# STM32MP157 register map
File version: 1.6
CPU: CM4 r0p1, little endian, no MPU, FPU, 4 interrupt priority bits
Registers are 32-bit, read-write, reset 0x0 unless marked. A register's access mark holds for its fields unless they carry their own. Offsets are from the block's base; [hi:lo] are bit positions; {n}, {i} and the like mark numbered series; 'fields as' and 'values as' point back to an identical list.

## OTG
Base 0x49000000
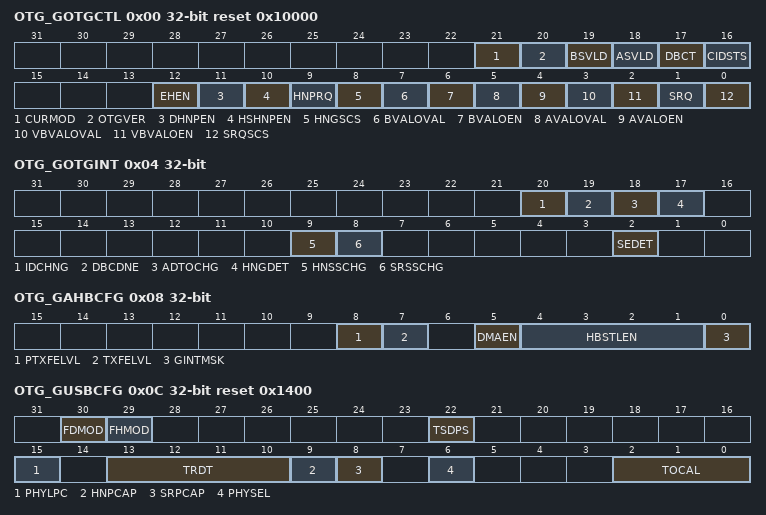
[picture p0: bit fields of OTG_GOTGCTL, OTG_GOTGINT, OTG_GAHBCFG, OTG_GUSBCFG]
0x00 OTG_GOTGCTL access per field reset 0x10000 — The OTG_GOTGCTL register controls the behavior and reflects the status of the OTG function of the core.
  [21] CURMOD ro, [20] OTGVER rw, [19] BSVLD ro, [18] ASVLD ro, [17] DBCT ro, [16] CIDSTS ro, [12] EHEN rw, [11] DHNPEN rw, [10] HSHNPEN rw, [9] HNPRQ rw, [8] HNGSCS ro, [7] BVALOVAL rw, [6] BVALOEN rw, [5] AVALOVAL rw, [4] AVALOEN rw, [3] VBVALOVAL rw, [2] VBVALOEN rw, [1] SRQ rw, [0] SRQSCS ro
0x04 OTG_GOTGINT — The application reads this register whenever there is an OTG interrupt and clears the bits in this register to clear the OTG interrupt.
  [20] IDCHNG, [19] DBCDNE, [18] ADTOCHG, [17] HNGDET, [9] HNSSCHG, [8] SRSSCHG, [2] SEDET
0x08 OTG_GAHBCFG — This register can be used to configure the core after power-on or a change in mode. This register mainly contains AHB system-related configuration parameters. Do not change this register after the initial programming. The application must program this register before starting any transactions on either the AHB or the USB.
  [8] PTXFELVL, [7] TXFELVL, [5] DMAEN, [4:1] HBSTLEN, [0] GINTMSK
0x0C OTG_GUSBCFG reset 0x1400 — This register can be used to configure the core after power-on or a changing to host mode or device mode. It contains USB and USB-PHY related configuration parameters. The application must program this register before starting any transactions on either the AHB or the USB. Do not make changes to this register after the initial programming.
  [30] FDMOD, [29] FHMOD, [22] TSDPS, [15] PHYLPC, [13:10] TRDT, [9] HNPCAP, [8] SRPCAP, [6] PHYSEL, [2:0] TOCAL
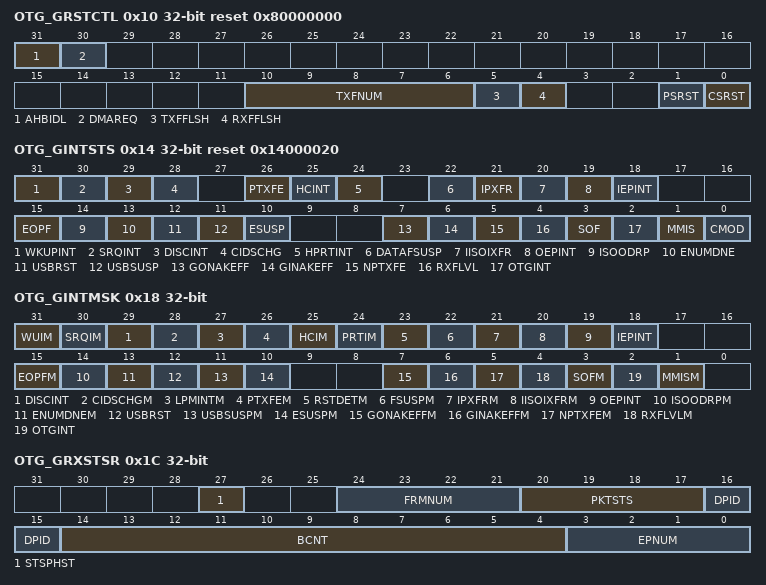
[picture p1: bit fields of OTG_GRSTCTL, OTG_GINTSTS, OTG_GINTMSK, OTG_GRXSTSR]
0x10 OTG_GRSTCTL access per field reset 0x80000000 — The application uses this register to reset various hardware features inside the core.
  [31] AHBIDL ro, [30] DMAREQ ro, [10:6] TXFNUM rw, [5] TXFFLSH rw, [4] RXFFLSH rw, [1] PSRST rw, [0] CSRST rw
0x14 OTG_GINTSTS access per field reset 0x14000020 — This register interrupts the application for system-level events in the current mode (device mode or host mode). Some of the bits in this register are valid only in host mode, while others are valid in device mode only. This register also indicates the current mode. To clear the interrupt status bits of the rc_w1 type, the application must write 1 into the bit. The FIFO status interrupts are read-only; once software reads from or writes to the FIFO while servicing these interrupts, FIFO interrupt conditions are cleared automatically. The application must clear the OTG_GINTSTS register at initialization before unmasking the interrupt bit to avoid any interrupts generated prior to initialization.
  [31] WKUPINT rw, [30] SRQINT rw, [29] DISCINT rw, [28] CIDSCHG rw, [26] PTXFE ro, [25] HCINT ro, [24] HPRTINT ro, [22] DATAFSUSP rw, [21] IPXFR rw, [20] IISOIXFR rw, [19] OEPINT ro, [18] IEPINT ro, [15] EOPF rw, [14] ISOODRP rw, [13] ENUMDNE rw, [12] USBRST rw, [11] USBSUSP rw, [10] ESUSP rw, [7] GONAKEFF ro, [6] GINAKEFF ro, [5] NPTXFE ro, [4] RXFLVL ro, [3] SOF rw, [2] OTGINT ro, [1] MMIS rw, [0] CMOD ro
0x18 OTG_GINTMSK access per field — This register works with the core interrupt register to interrupt the application. When an interrupt bit is masked, the interrupt associated with that bit is not generated. However, the core interrupt (OTG_GINTSTS) register bit corresponding to that interrupt is still set.
  [31] WUIM rw, [30] SRQIM rw, [29] DISCINT rw, [28] CIDSCHGM rw, [27] LPMINTM rw, [26] PTXFEM rw, [25] HCIM rw, [24] PRTIM ro, [23] RSTDETM rw, [22] FSUSPM rw, [21] IPXFRM rw, [20] IISOIXFRM rw, [19] OEPINT rw, [18] IEPINT rw, [15] EOPFM rw, [14] ISOODRPM rw, [13] ENUMDNEM rw, [12] USBRST rw, [11] USBSUSPM rw, [10] ESUSPM rw, [7] GONAKEFFM rw, [6] GINAKEFFM rw, [5] NPTXFEM rw, [4] RXFLVLM rw, [3] SOFM rw, [2] OTGINT rw, [1] MMISM rw
0x1C OTG_GRXSTSR ro — This description is for register OTG_GRXSTSR in Device mode. A read to the receive status debug read register returns the contents of the top of the receive FIFO. The core ignores the receive status read when the receive FIFO is empty and returns a value of 0x00000000.
  [27] STSPHST, [24:21] FRMNUM, [20:17] PKTSTS, [16:15] DPID, [14:4] BCNT, [3:0] EPNUM
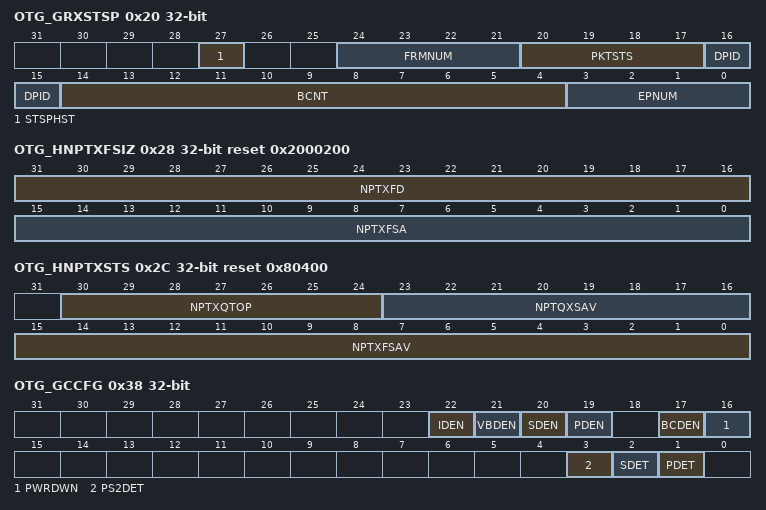
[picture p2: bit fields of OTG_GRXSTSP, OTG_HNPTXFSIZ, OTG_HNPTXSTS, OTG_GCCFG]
0x20 OTG_GRXSTSP ro — This description is for register OTG_GRXSTSP in Device mode. Similarly to OTG_GRXSTSR (receive status debug read register) where a read returns the contents of the top of the receive FIFO, a read to OTG_GRXSTSP (receive status read and pop register) additionally pops the top data entry out of the Rx FIFO. The core ignores the receive status pop/read when the receive FIFO is empty and returns a value of 0x00000000. The application must only pop the receive status FIFO when the receive FIFO non-empty bit of the core interrupt register (RXFLVL bit in OTG_GINTSTS) is asserted.
  fields as OTG_GRXSTSR
0x24 OTG_GRXFSIZ reset 0x400 — The application can program the RAM size that must be allocated to the Rx FIFO.
  [15:0] RXFD
0x28 OTG_HNPTXFSIZ reset 0x2000200 — Host mode
  [31:16] NPTXFD, [15:0] NPTXFSA
0x2C OTG_HNPTXSTS ro reset 0x80400 — In device mode, this register is not valid. This read-only register contains the free space information for the non-periodic Tx FIFO and the non-periodic transmit request queue.
  [30:24] NPTXQTOP, [23:16] NPTQXSAV, [15:0] NPTXFSAV
0x38 OTG_GCCFG access per field — OTG general core configuration register
  [22] IDEN rw, [21] VBDEN rw, [20] SDEN rw, [19] PDEN rw, [17] BCDEN rw, [16] PWRDWN rw, [3] PS2DET ro, [2] SDET ro, [1] PDET ro
0x3C OTG_CID reset 0x4000 — This is a register containing the Product ID as reset value.
  [31:0] PRODUCT_ID
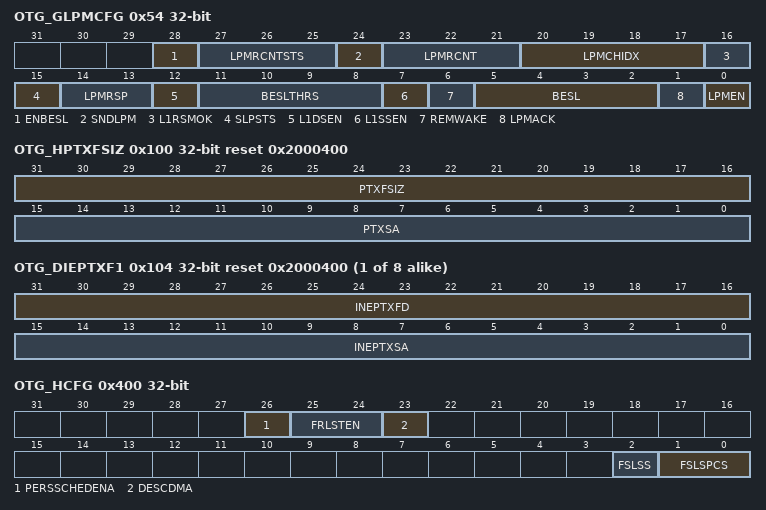
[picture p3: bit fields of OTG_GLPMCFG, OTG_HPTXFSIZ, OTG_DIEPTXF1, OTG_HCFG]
0x54 OTG_GLPMCFG access per field — OTG core LPM configuration register
  [28] ENBESL rw, [27:25] LPMRCNTSTS ro, [24] SNDLPM rw, [23:21] LPMRCNT rw, [20:17] LPMCHIDX rw, [16] L1RSMOK ro, [15] SLPSTS ro, [14:13] LPMRSP ro, [12] L1DSEN rw, [11:8] BESLTHRS rw, [7] L1SSEN rw, [6] REMWAKE rw, [5:2] BESL rw, [1] LPMACK rw, [0] LPMEN rw
0x100 OTG_HPTXFSIZ reset 0x2000400 — OTG host periodic transmit FIFO size register
  [31:16] PTXFSIZ, [15:0] PTXSA
{0x100+4i} OTG_DIEPTXF{i} reset 0x2000400 (i=1..8) — OTG device IN endpoint transmit FIFO {i} size register
  [31:16] INEPTXFD, [15:0] INEPTXSA
0x400 OTG_HCFG access per field — This register configures the core after power-on. Do not make changes to this register after initializing the host.
  [26] PERSSCHEDENA rw, [25:24] FRLSTEN rw, [23] DESCDMA rw, [2] FSLSS ro, [1:0] FSLSPCS rw
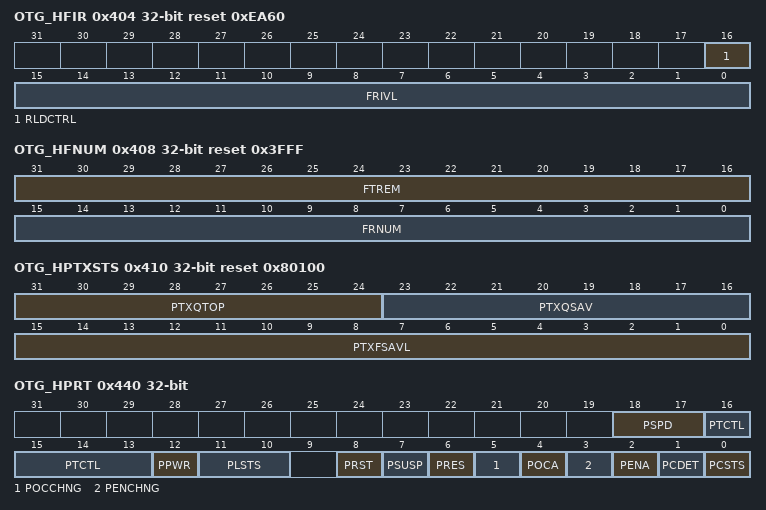
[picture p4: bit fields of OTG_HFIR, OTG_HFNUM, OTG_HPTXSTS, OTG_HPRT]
0x404 OTG_HFIR reset 0xEA60 — This register stores the frame interval information for the current speed to which the OTG controller has enumerated.
  [16] RLDCTRL, [15:0] FRIVL
0x408 OTG_HFNUM ro reset 0x3FFF — This register indicates the current frame number. It also indicates the time remaining (in terms of the number of PHY clocks) in the current frame.
  [31:16] FTREM, [15:0] FRNUM
0x410 OTG_HPTXSTS ro reset 0x80100 — This read-only register contains the free space information for the periodic Tx FIFO and the periodic transmit request queue.
  [31:24] PTXQTOP, [23:16] PTXQSAV, [15:0] PTXFSAVL
0x414 OTG_HAINT ro — When a significant event occurs on a channel, the host all channels interrupt register interrupts the application using the host channels interrupt bit of the core interrupt register (HCINT bit in OTG_GINTSTS). This is shown in Figure724. There is one interrupt bit per channel, up to a maximum of 16 bits. Bits in this register are set and cleared when the application sets and clears bits in the corresponding host channel-x interrupt register.
  [15:0] HAINT
0x418 OTG_HAINTMSK — The host all channel interrupt mask register works with the host all channel interrupt register to interrupt the application when an event occurs on a channel. There is one interrupt mask bit per channel, up to a maximum of 16 bits.
  [15:0] HAINTM
0x41C OTG_HFLBADDR — This register holds the starting address of the frame list information (scatter/gather mode).
0x440 OTG_HPRT access per field — This register is available only in host mode. Currently, the OTG host supports only one port. A single register holds USB port-related information such as USB reset, enable, suspend, resume, connect status, and test mode for each port. It is shown in Figure724. The rc_w1 bits in this register can trigger an interrupt to the application through the host port interrupt bit of the core interrupt register (HPRTINT bit in OTG_GINTSTS). On a port interrupt, the application must read this register and clear the bit that caused the interrupt. For the rc_w1 bits, the application must write a 1 to the bit to clear the interrupt.
  [18:17] PSPD ro, [16:13] PTCTL rw, [12] PPWR rw, [11:10] PLSTS ro, [8] PRST rw, [7] PSUSP rw, [6] PRES rw, [5] POCCHNG rw, [4] POCA ro, [3] PENCHNG rw, [2] PENA rw, [1] PCDET rw, [0] PCSTS ro
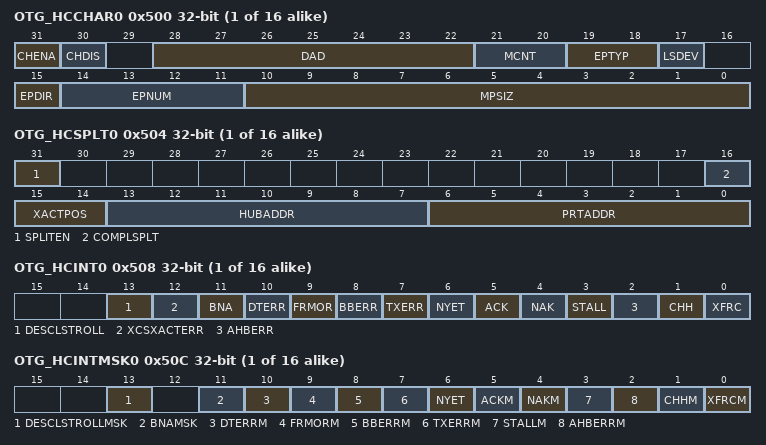
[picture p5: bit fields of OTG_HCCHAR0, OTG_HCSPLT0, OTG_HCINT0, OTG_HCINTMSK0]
{0x500+0x20*i} OTG_HCCHAR{i} (i=0..15) — OTG host channel {i} characteristics register
  [31] CHENA, [30] CHDIS, [28:22] DAD, [21:20] MCNT, [19:18] EPTYP, [17] LSDEV, [15] EPDIR, [14:11] EPNUM, [10:0] MPSIZ
{0x504+0x20*i} OTG_HCSPLT{i} (i=0..15) — OTG host channel {i} split control register
  [31] SPLITEN, [16] COMPLSPLT, [15:14] XACTPOS, [13:7] HUBADDR, [6:0] PRTADDR
{0x508+0x20*i} OTG_HCINT{i} (i=0..15) — This register indicates the status of a channel with respect to USB- and AHB-related events. It is shown in Figure724. The application must read this register when the host channels interrupt bit in the core interrupt register (HCINT bit in OTG_GINTSTS) is set. Before the application can read this register, it must first read the host all channels interrupt (OTG_HAINT) register to get the exact channel number for the host channel-x interrupt register. The application must clear the appropriate bit in this register to clear the corresponding bits in the OTG_HAINT and OTG_GINTSTS registers.
  [13] DESCLSTROLL, [12] XCSXACTERR, [11] BNA, [10] DTERR, [9] FRMOR, [8] BBERR, [7] TXERR, [6] NYET, [5] ACK, [4] NAK, [3] STALL, [2] AHBERR, [1] CHH, [0] XFRC
{0x50C+0x20*i} OTG_HCINTMSK{i} (i=0..15) — This register reflects the mask for each channel status described in the previous section.
  [13] DESCLSTROLLMSK, [11] BNAMSK, [10] DTERRM, [9] FRMORM, [8] BBERRM, [7] TXERRM, [6] NYET, [5] ACKM, [4] NAKM, [3] STALLM, [2] AHBERRM, [1] CHHM, [0] XFRCM
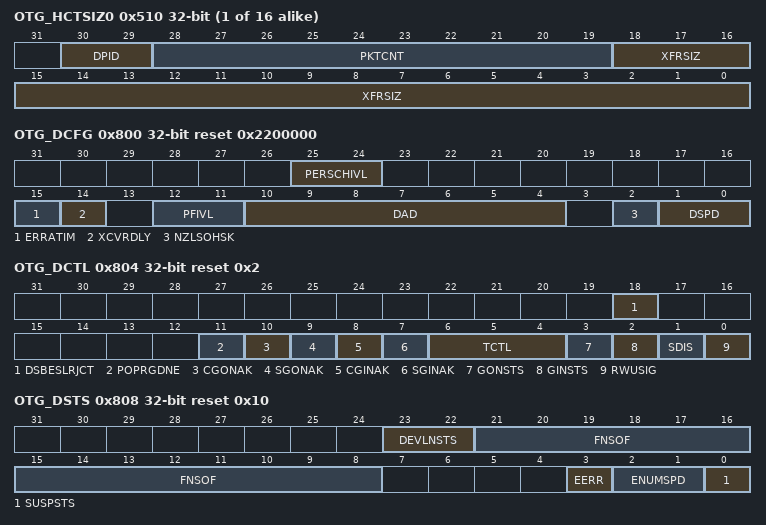
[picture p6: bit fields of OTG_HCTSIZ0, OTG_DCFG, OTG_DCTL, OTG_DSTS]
{0x510+0x20*i} OTG_HCTSIZ{i} (i=0..15) — OTG host channel {i} transfer size register
  [30:29] DPID, [28:19] PKTCNT, [18:0] XFRSIZ
{0x514+0x20*i} OTG_HCDMA{i} (i=0..15) — OTG host channel {i} DMA address register in buffer DMA [alternate]
  [31:0] DMAADDR
{0x51C+0x20*i} OTG_HCDMAB{i} ro (i=0..15) — OTG host channel-n DMA address buffer register
  [31:0] HCDMAB
0x800 OTG_DCFG reset 0x2200000 — This register configures the core in device mode after power-on or after certain control commands or enumeration. Do not make changes to this register after initial programming.
  [25:24] PERSCHIVL, [15] ERRATIM, [14] XCVRDLY, [12:11] PFIVL, [10:4] DAD, [2] NZLSOHSK, [1:0] DSPD
0x804 OTG_DCTL access per field reset 0x2 — OTG device control register
  [18] DSBESLRJCT rw, [11] POPRGDNE rw, [10] CGONAK wo, [9] SGONAK wo, [8] CGINAK wo, [7] SGINAK wo, [6:4] TCTL rw, [3] GONSTS ro, [2] GINSTS ro, [1] SDIS rw, [0] RWUSIG rw
0x808 OTG_DSTS ro reset 0x10 — This register indicates the status of the core with respect to USB-related events. It must be read on interrupts from the device all interrupts (OTG_DAINT) register.
  [23:22] DEVLNSTS, [21:8] FNSOF, [3] EERR, [2:1] ENUMSPD, [0] SUSPSTS
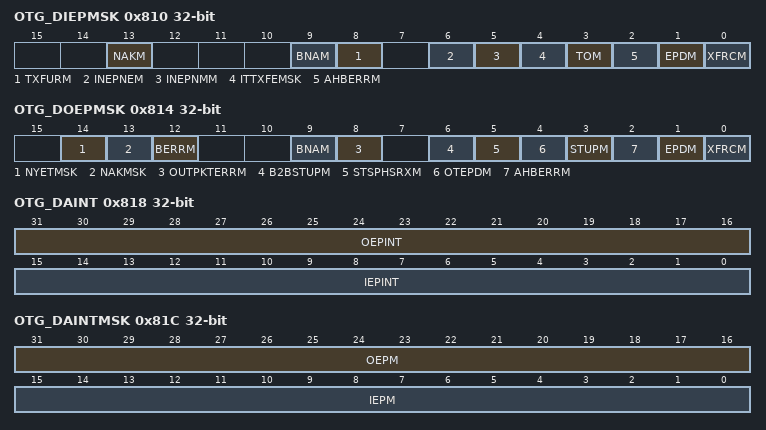
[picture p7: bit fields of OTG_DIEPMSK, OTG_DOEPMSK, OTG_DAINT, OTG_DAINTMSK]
0x810 OTG_DIEPMSK — This register works with each of the OTG_DIEPINTx registers for all endpoints to generate an interrupt per IN endpoint. The IN endpoint interrupt for a specific status in the OTG_DIEPINTx register can be masked by writing to the corresponding bit in this register. Status bits are masked by default.
  [13] NAKM, [9] BNAM, [8] TXFURM, [6] INEPNEM, [5] INEPNMM, [4] ITTXFEMSK, [3] TOM, [2] AHBERRM, [1] EPDM, [0] XFRCM
0x814 OTG_DOEPMSK — This register works with each of the OTG_DOEPINTx registers for all endpoints to generate an interrupt per OUT endpoint. The OUT endpoint interrupt for a specific status in the OTG_DOEPINTx register can be masked by writing into the corresponding bit in this register. Status bits are masked by default.
  [14] NYETMSK, [13] NAKMSK, [12] BERRM, [9] BNAM, [8] OUTPKTERRM, [6] B2BSTUPM, [5] STSPHSRXM, [4] OTEPDM, [3] STUPM, [2] AHBERRM, [1] EPDM, [0] XFRCM
0x818 OTG_DAINT ro — When a significant event occurs on an endpoint, a OTG_DAINT register interrupts the application using the device OUT endpoints interrupt bit or device IN endpoints interrupt bit of the OTG_GINTSTS register (OEPINT or IEPINT in OTG_GINTSTS, respectively). There is one interrupt bit per endpoint, up to a maximum of 16 bits for OUT endpoints and 16 bits for IN endpoints. For a bidirectional endpoint, the corresponding IN and OUT interrupt bits are used. Bits in this register are set and cleared when the application sets and clears bits in the corresponding device endpoint-x interrupt register (OTG_DIEPINTx/OTG_DOEPINTx).
  [31:16] OEPINT, [15:0] IEPINT
0x81C OTG_DAINTMSK — The OTG_DAINTMSK register works with the device endpoint interrupt register to interrupt the application when an event occurs on a device endpoint. However, the OTG_DAINT register bit corresponding to that interrupt is still set.
  [31:16] OEPM, [15:0] IEPM
0x828 OTG_DVBUSDIS reset 0x17D7 — This register specifies the VBUS discharge time after VBUS pulsing during SRP.
  [15:0] VBUSDT
0x82C OTG_DVBUSPULSE reset 0x5B8 — This register specifies the VBUS pulsing time during SRP.
  [15:0] DVBUSP
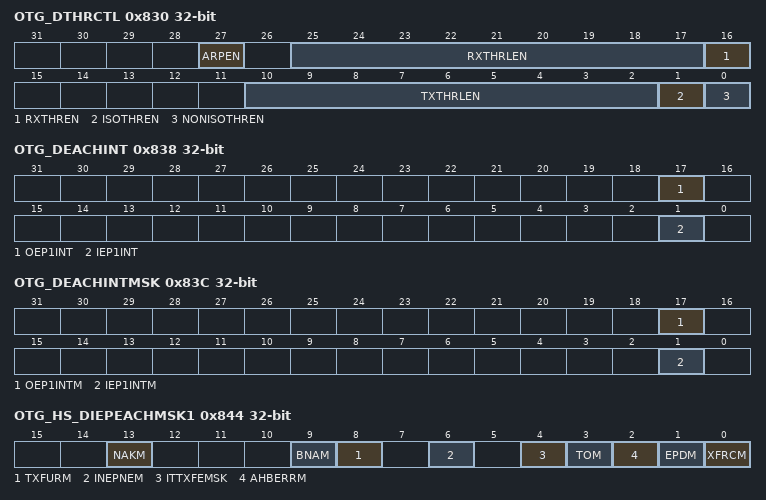
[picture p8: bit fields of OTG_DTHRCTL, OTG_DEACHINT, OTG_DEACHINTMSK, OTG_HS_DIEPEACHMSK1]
0x830 OTG_DTHRCTL — OTG device threshold control register
  [27] ARPEN, [25:17] RXTHRLEN, [16] RXTHREN, [10:2] TXTHRLEN, [1] ISOTHREN, [0] NONISOTHREN
0x834 OTG_DIEPEMPMSK — This register is used to control the IN endpoint FIFO empty interrupt generation (TXFE_OTG_DIEPINTx).
  [15:0] INEPTXFEM
0x838 OTG_DEACHINT ro — OTG device each endpoint interrupt register
  [17] OEP1INT, [1] IEP1INT
0x83C OTG_DEACHINTMSK — There is one interrupt bit for endpoint 1 IN and one interrupt bit for endpoint 1 OUT.
  [17] OEP1INTM, [1] IEP1INTM
0x844 OTG_HS_DIEPEACHMSK1 — This register works with the OTG_DIEPINT1 register to generate a dedicated interrupt OTG_HS_EP1_IN for endpoint #1. The IN endpoint interrupt for a specific status in the OTG_DOEPINT1 register can be masked by writing into the corresponding bit in this register. Status bits are masked by default.
  [13] NAKM, [9] BNAM, [8] TXFURM, [6] INEPNEM, [4] ITTXFEMSK, [3] TOM, [2] AHBERRM, [1] EPDM, [0] XFRCM
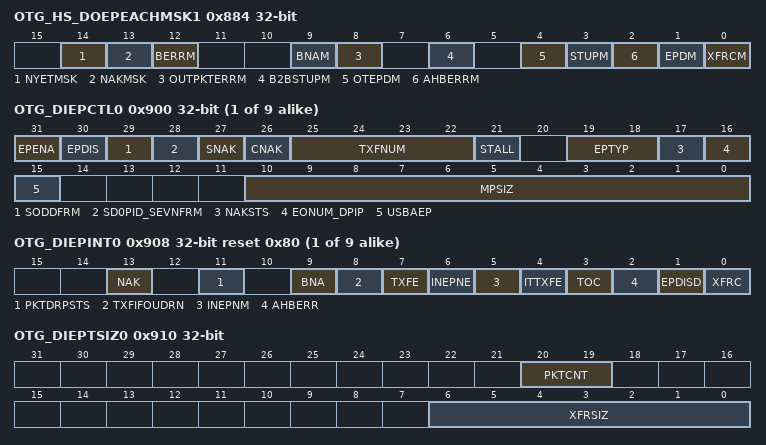
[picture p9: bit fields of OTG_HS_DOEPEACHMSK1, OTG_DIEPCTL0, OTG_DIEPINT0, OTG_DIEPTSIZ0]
0x884 OTG_HS_DOEPEACHMSK1 — This register works with the OTG_DOEPINT1 register to generate a dedicated interrupt OTG_HS_EP1_OUT for endpoint #1. The OUT endpoint interrupt for a specific status in the OTG_DOEPINT1 register can be masked by writing into the corresponding bit in this register. Status bits are masked by default.
  [14] NYETMSK, [13] NAKMSK, [12] BERRM, [9] BNAM, [8] OUTPKTERRM, [6] B2BSTUPM, [4] OTEPDM, [3] STUPM, [2] AHBERRM, [1] EPDM, [0] XFRCM
{0x900+0x20*i} OTG_DIEPCTL{i} access per field (i=0..8) — The application uses this register to control the behavior of each logical endpoint other than endpoint 0.
  [31] EPENA rw, [30] EPDIS rw, [29] SODDFRM wo, [28] SD0PID_SEVNFRM wo, [27] SNAK wo, [26] CNAK wo, [25:22] TXFNUM rw, [21] STALL rw, [19:18] EPTYP rw, [17] NAKSTS ro, [16] EONUM_DPIP ro, [15] USBAEP rw, [10:0] MPSIZ rw
{0x908+0x20*i} OTG_DIEPINT{i} access per field reset 0x80 (i=0..8) — This register indicates the status of an endpoint with respect to USB- and AHB-related events. It is shown in Figure724. The application must read this register when the IN endpoints interrupt bit of the core interrupt register (IEPINT in OTG_GINTSTS) is set. Before the application can read this register, it must first read the device all endpoints interrupt (OTG_DAINT) register to get the exact endpoint number for the device endpoint-x interrupt register. The application must clear the appropriate bit in this register to clear the corresponding bits in the OTG_DAINT and OTG_GINTSTS registers.
  [13] NAK rw, [11] PKTDRPSTS rw, [9] BNA rw, [8] TXFIFOUDRN rw, [7] TXFE ro, [6] INEPNE ro, [5] INEPNM rw, [4] ITTXFE rw, [3] TOC rw, [2] AHBERR rw, [1] EPDISD rw, [0] XFRC rw
0x910 OTG_DIEPTSIZ0 — The application must modify this register before enabling endpoint 0.
  [20:19] PKTCNT, [6:0] XFRSIZ
{0x914+0x20*i} OTG_DIEPDMA{i} (i=0..8) — OTG device IN endpoint {i} DMA address register
  [31:0] DMAADDR
{0x918+0x20*i} OTG_DTXFSTS{i} ro reset 0x200 (i=0..8) — This read-only register contains the free space information for the device IN endpoint Tx FIFO.
  [15:0] INEPTFSAV
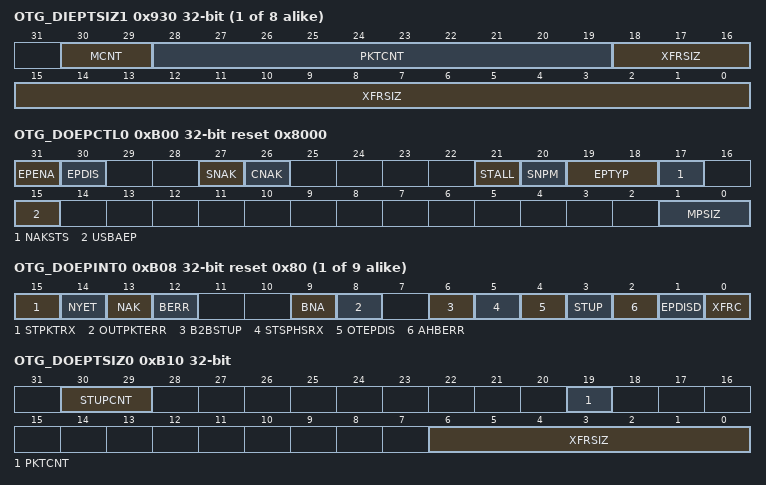
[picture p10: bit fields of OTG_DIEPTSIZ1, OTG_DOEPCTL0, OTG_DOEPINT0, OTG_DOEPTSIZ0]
{0x910+0x20*i} OTG_DIEPTSIZ{i} (i=1..8) — The application must modify this register before enabling the endpoint. Once the endpoint is enabled using the endpoint enable bit in the OTG_DIEPCTLx registers (EPENA bit in OTG_DIEPCTLx), the core modifies this register. The application can only read this register once the core has cleared the endpoint enable bit.
  [30:29] MCNT, [28:19] PKTCNT, [18:0] XFRSIZ
0xB00 OTG_DOEPCTL0 access per field reset 0x8000 — This section describes the OTG_DOEPCTL0 register.
  [31] EPENA wo, [30] EPDIS ro, [27] SNAK wo, [26] CNAK wo, [21] STALL rw, [20] SNPM rw, [19:18] EPTYP ro, [17] NAKSTS ro, [15] USBAEP ro, [1:0] MPSIZ ro
{0xB08+0x20*i} OTG_DOEPINT{i} reset 0x80 (i=0..8) — This register indicates the status of an endpoint with respect to USB- and AHB-related events. It is shown in Figure724. The application must read this register when the OUT endpoints interrupt bit of the OTG_GINTSTS register (OEPINT bit in OTG_GINTSTS) is set. Before the application can read this register, it must first read the OTG_DAINT register to get the exact endpoint number for the OTG_DOEPINTx register. The application must clear the appropriate bit in this register to clear the corresponding bits in the OTG_DAINT and OTG_GINTSTS registers.
  [15] STPKTRX, [14] NYET, [13] NAK, [12] BERR, [9] BNA, [8] OUTPKTERR, [6] B2BSTUP, [5] STSPHSRX, [4] OTEPDIS, [3] STUP, [2] AHBERR, [1] EPDISD, [0] XFRC
0xB10 OTG_DOEPTSIZ0 — The application must modify this register before enabling endpoint 0.
  [30:29] STUPCNT, [19] PKTCNT, [6:0] XFRSIZ
{0xB14+0x20*i} OTG_DOEPDMA{i} (i=0..8) — OTG device OUT endpoint {i} DMA address register
  [31:0] DMAADDR
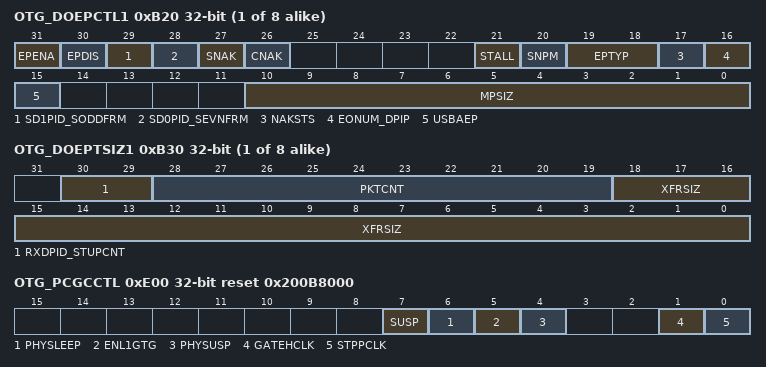
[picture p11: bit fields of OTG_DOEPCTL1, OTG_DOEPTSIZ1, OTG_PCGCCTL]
{0xB00+0x20*i} OTG_DOEPCTL{i} access per field (i=1..8) — The application uses this register to control the behavior of each logical endpoint other than endpoint 0.
  [31] EPENA rw, [30] EPDIS rw, [29] SD1PID_SODDFRM wo, [28] SD0PID_SEVNFRM wo, [27] SNAK wo, [26] CNAK wo, [21] STALL rw, [20] SNPM rw, [19:18] EPTYP rw, [17] NAKSTS ro, [16] EONUM_DPIP ro, [15] USBAEP rw, [10:0] MPSIZ rw
{0xB10+0x20*i} OTG_DOEPTSIZ{i} (i=1..8) — The application must modify this register before enabling the endpoint. Once the endpoint is enabled using endpoint enable bit of the OTG_DOEPCTLx registers (EPENA bit in OTG_DOEPCTLx), the core modifies this register. The application can only read this register once the core has cleared the endpoint enable bit.
  [30:29] RXDPID_STUPCNT, [28:19] PKTCNT, [18:0] XFRSIZ
0xE00 OTG_PCGCCTL access per field reset 0x200B8000 — This register is available in host and device modes.
  [7] SUSP ro, [6] PHYSLEEP ro, [5] ENL1GTG rw, [4] PHYSUSP ro, [1] GATEHCLK rw, [0] STPPCLK rw
